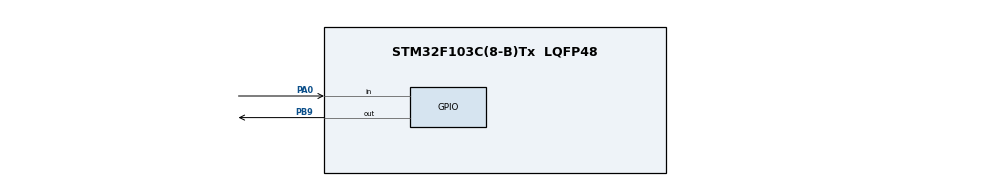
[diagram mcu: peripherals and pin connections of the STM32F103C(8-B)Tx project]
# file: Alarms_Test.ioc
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Mcu.Family=STM32F1
RCC.APB2Freq_Value=8000000
PD1-OSC_OUT.Mode=HSE-External-Oscillator
PA14.Mode=Serial_Wire
PA13.Mode=Serial_Wire
Mcu.Name=STM32F103C(8-B)Tx
PD0-OSC_IN.Signal=RCC_OSC_IN
PB9.Signal=GPIO_Output
Mcu.Package=LQFP48
ProjectManager.StackSize=0x400
PA0-WKUP.Signal=GPIO_Input
PD1-OSC_OUT.Signal=RCC_OSC_OUT
PA13.Signal=SYS_JTMS-SWDIO
PA14.Signal=SYS_JTCK-SWCLK
ProjectManager.HeapSize=0x200
ProjectManager.TargetToolchain=STM32CubeIDE
NVIC.PriorityGroup=NVIC_PRIORITYGROUP_4
RCC.APB1Freq_Value=8000000
PD0-OSC_IN.Mode=HSE-External-Oscillator
board=custom

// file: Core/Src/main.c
/* USER CODE BEGIN Header */
/**
  ******************************************************************************
  * @file           : main.c
  * @brief          : Main program body
  ******************************************************************************
  * @attention
  *
  * <h2><center>&copy; Copyright (c) 2021 STMicroelectronics.
  * All rights reserved.</center></h2>
  *
  * This software component is licensed by ST under BSD 3-Clause license,
  * the "License"; You may not use this file except in compliance with the
  * License. You may obtain a copy of the License at:
  *                        opensource.org/licenses/BSD-3-Clause
  *
  ******************************************************************************
  */
/* USER CODE END Header */
#include "main.h"

/* USER CODE BEGIN Includes */
#include "antirrebote.h"
#include "timers.h"
#include "alarm.h"
/* USER CODE END Includes */

/* USER CODE BEGIN PM */
#define 	ALARM_TYPE_TO_TEST 	LONG_SINGLE_BEEP
/* En el archivo alarm.h...

typedef enum{
	NONE,
	SINGLE_BEEP,
	DOUBLE_BEEP,
	TRIPLE_BEEP,
	QUADRUPLE_BEEP,
	LONG_SINGLE_BEEP
} AlarmType;

*/

/* USER CODE END PM */

void SystemClock_Config(void);
static void MX_GPIO_Init(void);

int main(void)
{
  /* USER CODE BEGIN 1 */
	Alarm alarma;
	debouncedButton sw;
  /* USER CODE END 1 */

  /* MCU Configuration--------------------------------------------------------*/

  /* Reset of all peripherals, Initializes the Flash interface and the Systick. */
  HAL_Init();

  /* Configure the system clock */
  SystemClock_Config();

  /* Initialize all configured peripherals */
  MX_GPIO_Init();
  /* USER CODE BEGIN 2 */

  initAlarm( &alarma );
  initDebounce( &sw, ACTIVE_HIGH, 20);

  //INITS

  /* USER CODE END 2 */

  /* Infinite loop */
  while (1)
  {

    /* USER CODE BEGIN 3 */

	  FSM_Alarm( &alarma );
	  FSM_Debounce( &sw, HAL_GPIO_ReadPin(GPIOA, GPIO_PIN_0) );
	  if( btnEdgeToActive( &sw ) ){
		  // Activo
		  setAlarm( &alarma, ALARM_TYPE_TO_TEST );
	  }
	  else if( btnEdgeToIDLE( &sw ) ){
		  // IDLE
		  resetAlarm( &alarma );
	  }

	  // LOOP

  }
  /* USER CODE END 3 */
}

void SystemClock_Config(void)
{
  RCC_OscInitTypeDef RCC_OscInitStruct = {0};
  RCC_ClkInitTypeDef RCC_ClkInitStruct = {0};

  /** Initializes the RCC Oscillators according to the specified parameters
  * in the RCC_OscInitTypeDef structure.
  */
  RCC_OscInitStruct.OscillatorType = RCC_OSCILLATORTYPE_HSI;
  RCC_OscInitStruct.HSIState = RCC_HSI_ON;
  RCC_OscInitStruct.HSICalibrationValue = RCC_HSICALIBRATION_DEFAULT;
  RCC_OscInitStruct.PLL.PLLState = RCC_PLL_NONE;
  if (HAL_RCC_OscConfig(&RCC_OscInitStruct) != HAL_OK)
  {
    Error_Handler();
  }
  /** Initializes the CPU, AHB and APB buses clocks
  */
  RCC_ClkInitStruct.ClockType = RCC_CLOCKTYPE_HCLK|RCC_CLOCKTYPE_SYSCLK
                              |RCC_CLOCKTYPE_PCLK1|RCC_CLOCKTYPE_PCLK2;
  RCC_ClkInitStruct.SYSCLKSource = RCC_SYSCLKSOURCE_HSI;
  RCC_ClkInitStruct.AHBCLKDivider = RCC_SYSCLK_DIV1;
  RCC_ClkInitStruct.APB1CLKDivider = RCC_HCLK_DIV1;
  RCC_ClkInitStruct.APB2CLKDivider = RCC_HCLK_DIV1;

  if (HAL_RCC_ClockConfig(&RCC_ClkInitStruct, FLASH_LATENCY_0) != HAL_OK)
  {
    Error_Handler();
  }
}

static void MX_GPIO_Init(void)
{
  GPIO_InitTypeDef GPIO_InitStruct = {0};

  /* GPIO Ports Clock Enable */
  __HAL_RCC_GPIOD_CLK_ENABLE();
  __HAL_RCC_GPIOA_CLK_ENABLE();
  __HAL_RCC_GPIOB_CLK_ENABLE();

  /*Configure GPIO pin Output Level */
  HAL_GPIO_WritePin(GPIOB, GPIO_PIN_9, GPIO_PIN_RESET);

  /*Configure GPIO pin : PA0 */
  GPIO_InitStruct.Pin = GPIO_PIN_0;
  GPIO_InitStruct.Mode = GPIO_MODE_INPUT;
  GPIO_InitStruct.Pull = GPIO_NOPULL;
  HAL_GPIO_Init(GPIOA, &GPIO_InitStruct);

  /*Configure GPIO pin : PB9 */
  GPIO_InitStruct.Pin = GPIO_PIN_9;
  GPIO_InitStruct.Mode = GPIO_MODE_OUTPUT_PP;
  GPIO_InitStruct.Pull = GPIO_NOPULL;
  GPIO_InitStruct.Speed = GPIO_SPEED_FREQ_LOW;
  HAL_GPIO_Init(GPIOB, &GPIO_InitStruct);

}

void Error_Handler(void)
{
  __disable_irq();
  while (1)
  {
  }
}

/************************ (C) COPYRIGHT STMicroelectronics *****END OF FILE****/
